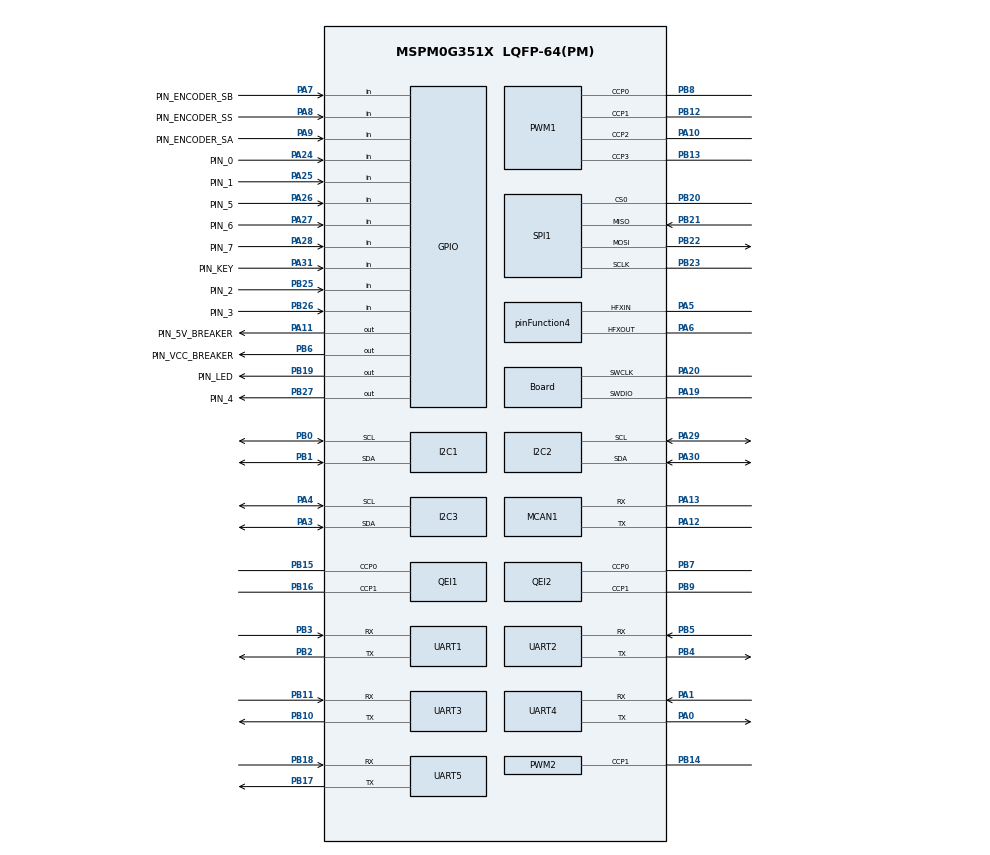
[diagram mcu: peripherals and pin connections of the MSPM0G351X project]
/**
 * @cliArgs --device "MSPM0G351X" --part "Default" --package "LQFP-64(PM)" --product "mspm0_sdk@2.10.00.04"
 * @versions {"tool":"1.27.0+4565"}
 */

/**
 * Import the modules used in this configuration.
 */
const Board  = scripting.addModule("/ti/driverlib/Board");
const GPIO   = scripting.addModule("/ti/driverlib/GPIO", {}, false);
const GPIO1  = GPIO.addInstance();
const GPIO2  = GPIO.addInstance();
const GPIO3  = GPIO.addInstance();
const GPIO4  = GPIO.addInstance();
const I2C    = scripting.addModule("/ti/driverlib/I2C", {}, false);
const I2C1   = I2C.addInstance();
const I2C2   = I2C.addInstance();
const I2C3   = I2C.addInstance();
const MCAN   = scripting.addModule("/ti/driverlib/MCAN", {}, false);
const MCAN1  = MCAN.addInstance();
const PWM    = scripting.addModule("/ti/driverlib/PWM", {}, false);
const PWM1   = PWM.addInstance();
const PWM2   = PWM.addInstance();
const QEI    = scripting.addModule("/ti/driverlib/QEI", {}, false);
const QEI1   = QEI.addInstance();
const QEI2   = QEI.addInstance();
const SPI    = scripting.addModule("/ti/driverlib/SPI", {}, false);
const SPI1   = SPI.addInstance();
const SYSCTL = scripting.addModule("/ti/driverlib/SYSCTL");
const UART   = scripting.addModule("/ti/driverlib/UART", {}, false);
const UART1  = UART.addInstance();
const UART2  = UART.addInstance();
const UART3  = UART.addInstance();
const UART4  = UART.addInstance();
const UART5  = UART.addInstance();

/**
 * Write custom configuration values to the imported modules.
 */
const divider2       = system.clockTree["HFCLK4MFPCLKDIV"];
divider2.divideValue = 10;

const divider9       = system.clockTree["UDIV"];
divider9.divideValue = 2;

const gate8  = system.clockTree["MFPCLKGATE"];
gate8.enable = true;

const mux4       = system.clockTree["EXHFMUX"];
mux4.inputSelect = "EXHFMUX_XTAL";

const mux8       = system.clockTree["HSCLKMUX"];
mux8.inputSelect = "HSCLKMUX_SYSPLL2X";

const mux10       = system.clockTree["MFPCLKMUX"];
mux10.inputSelect = "MFPCLKMUX_HFCLK";

const mux12       = system.clockTree["SYSPLLMUX"];
mux12.inputSelect = "zSYSPLLMUX_HFCLK";

const pinFunction4                        = system.clockTree["HFXT"];
pinFunction4.inputFreq                    = 40;
pinFunction4.enable                       = true;
pinFunction4.HFXTStartup                  = 255;
pinFunction4.HFCLKMonitor                 = true;
pinFunction4.peripheral.$assign           = "SYSCTL";
pinFunction4.peripheral.hfxInPin.$assign  = "PA5";
pinFunction4.peripheral.hfxOutPin.$assign = "PA6";

Board.configureUnused             = true;
Board.unusedDirection             = "INPUT";
Board.unusedInternalResistor      = "PULL_DOWN";
Board.peripheral.$assign          = "DEBUGSS";
Board.peripheral.swclkPin.$assign = "PA20";
Board.peripheral.swdioPin.$assign = "PA19";

GPIO1.$name                                 = "BREAKER";
GPIO1.associatedPins.create(2);
GPIO1.associatedPins[0].$name               = "PIN_VCC_BREAKER";
GPIO1.associatedPins[0].assignedPort        = "PORTB";
GPIO1.associatedPins[0].assignedPortSegment = "Lower";
GPIO1.associatedPins[0].assignedPin         = "6";
GPIO1.associatedPins[0].pin.$assign         = "PB6";
GPIO1.associatedPins[1].$name               = "PIN_5V_BREAKER";
GPIO1.associatedPins[1].assignedPort        = "PORTA";
GPIO1.associatedPins[1].assignedPin         = "11";
GPIO1.associatedPins[1].pin.$assign         = "PA11";

GPIO2.$name                          = "IO";
GPIO2.associatedPins.create(8);
GPIO2.associatedPins[0].$name        = "PIN_0";
GPIO2.associatedPins[0].direction    = "INPUT";
GPIO2.associatedPins[0].assignedPort = "PORTA";
GPIO2.associatedPins[0].assignedPin  = "24";
GPIO2.associatedPins[0].pin.$assign  = "PA24";
GPIO2.associatedPins[1].$name        = "PIN_1";
GPIO2.associatedPins[1].direction    = "INPUT";
GPIO2.associatedPins[1].assignedPort = "PORTA";
GPIO2.associatedPins[1].assignedPin  = "25";
GPIO2.associatedPins[1].pin.$assign  = "PA25";
GPIO2.associatedPins[2].$name        = "PIN_2";
GPIO2.associatedPins[2].direction    = "INPUT";
GPIO2.associatedPins[2].assignedPort = "PORTB";
GPIO2.associatedPins[2].assignedPin  = "25";
GPIO2.associatedPins[2].pin.$assign  = "PB25";
GPIO2.associatedPins[3].$name        = "PIN_3";
GPIO2.associatedPins[3].direction    = "INPUT";
GPIO2.associatedPins[3].assignedPort = "PORTB";
GPIO2.associatedPins[3].assignedPin  = "26";
GPIO2.associatedPins[3].pin.$assign  = "PB26";
GPIO2.associatedPins[4].$name        = "PIN_4";
GPIO2.associatedPins[4].assignedPort = "PORTB";
GPIO2.associatedPins[4].assignedPin  = "27";
GPIO2.associatedPins[4].pin.$assign  = "PB27";
GPIO2.associatedPins[5].$name        = "PIN_5";
GPIO2.associatedPins[5].direction    = "INPUT";
GPIO2.associatedPins[5].assignedPort = "PORTA";
GPIO2.associatedPins[5].assignedPin  = "26";
GPIO2.associatedPins[5].pin.$assign  = "PA26";
GPIO2.associatedPins[6].$name        = "PIN_6";
GPIO2.associatedPins[6].direction    = "INPUT";
GPIO2.associatedPins[6].assignedPort = "PORTA";
GPIO2.associatedPins[6].assignedPin  = "27";
GPIO2.associatedPins[6].pin.$assign  = "PA27";
GPIO2.associatedPins[7].$name        = "PIN_7";
GPIO2.associatedPins[7].assignedPort = "PORTA";
GPIO2.associatedPins[7].assignedPin  = "28";
GPIO2.associatedPins[7].direction    = "INPUT";
GPIO2.associatedPins[7].pin.$assign  = "PA28";

GPIO3.$name                          = "KEY";
GPIO3.associatedPins.create(4);
GPIO3.associatedPins[0].$name        = "PIN_KEY";
GPIO3.associatedPins[0].direction    = "INPUT";
GPIO3.associatedPins[0].assignedPort = "PORTA";
GPIO3.associatedPins[0].assignedPin  = "31";
GPIO3.associatedPins[0].polarity     = "RISE";
GPIO3.associatedPins[0].interruptEn  = true;
GPIO3.associatedPins[0].pin.$assign  = "PA31";
GPIO3.associatedPins[1].assignedPort = "PORTA";
GPIO3.associatedPins[1].assignedPin  = "9";
GPIO3.associatedPins[1].$name        = "PIN_ENCODER_SA";
GPIO3.associatedPins[1].direction    = "INPUT";
GPIO3.associatedPins[1].polarity     = "RISE_FALL";
GPIO3.associatedPins[1].interruptEn  = true;
GPIO3.associatedPins[1].pin.$assign  = "PA9";
GPIO3.associatedPins[2].$name        = "PIN_ENCODER_SS";
GPIO3.associatedPins[2].assignedPort = "PORTA";
GPIO3.associatedPins[2].assignedPin  = "8";
GPIO3.associatedPins[2].direction    = "INPUT";
GPIO3.associatedPins[2].polarity     = "RISE";
GPIO3.associatedPins[2].interruptEn  = true;
GPIO3.associatedPins[2].pin.$assign  = "PA8";
GPIO3.associatedPins[3].$name        = "PIN_ENCODER_SB";
GPIO3.associatedPins[3].assignedPort = "PORTA";
GPIO3.associatedPins[3].assignedPin  = "7";
GPIO3.associatedPins[3].direction    = "INPUT";
GPIO3.associatedPins[3].polarity     = "RISE_FALL";
GPIO3.associatedPins[3].interruptEn  = true;
GPIO3.associatedPins[3].pin.$assign  = "PA7";

GPIO4.$name                          = "LED";
GPIO4.associatedPins[0].$name        = "PIN_LED";
GPIO4.associatedPins[0].assignedPort = "PORTB";
GPIO4.associatedPins[0].assignedPin  = "19";
GPIO4.associatedPins[0].pin.$assign  = "PB19";

I2C1.$name                             = "I2C_0_OLED";
I2C1.basicEnableController             = true;
I2C1.basicControllerBusSpeed           = 400000;
I2C1.peripheral.$assign                = "I2C0";
I2C1.peripheral.sdaPin.$assign         = "PB1";
I2C1.peripheral.sclPin.$assign         = "PB0";
I2C1.sdaPinConfig.hideOutputInversion  = scripting.forceWrite(false);
I2C1.sdaPinConfig.onlyInternalResistor = scripting.forceWrite(false);
I2C1.sdaPinConfig.passedPeripheralType = scripting.forceWrite("Digital");
I2C1.sdaPinConfig.$name                = "ti_driverlib_gpio_GPIOPinGeneric14";
I2C1.sclPinConfig.hideOutputInversion  = scripting.forceWrite(false);
I2C1.sclPinConfig.onlyInternalResistor = scripting.forceWrite(false);
I2C1.sclPinConfig.passedPeripheralType = scripting.forceWrite("Digital");
I2C1.sclPinConfig.$name                = "ti_driverlib_gpio_GPIOPinGeneric15";

I2C2.$name                             = "I2C_2";
I2C2.basicEnableController             = true;
I2C2.basicControllerBusSpeed           = 400000;
I2C2.peripheral.$assign                = "I2C2";
I2C2.peripheral.sdaPin.$assign         = "PA30";
I2C2.peripheral.sclPin.$assign         = "PA29";
I2C2.sdaPinConfig.hideOutputInversion  = scripting.forceWrite(false);
I2C2.sdaPinConfig.onlyInternalResistor = scripting.forceWrite(false);
I2C2.sdaPinConfig.passedPeripheralType = scripting.forceWrite("Digital");
I2C2.sdaPinConfig.$name                = "ti_driverlib_gpio_GPIOPinGeneric16";
I2C2.sclPinConfig.hideOutputInversion  = scripting.forceWrite(false);
I2C2.sclPinConfig.onlyInternalResistor = scripting.forceWrite(false);
I2C2.sclPinConfig.passedPeripheralType = scripting.forceWrite("Digital");
I2C2.sclPinConfig.$name                = "ti_driverlib_gpio_GPIOPinGeneric17";

I2C3.$name                             = "I2C_1";
I2C3.basicEnableController             = true;
I2C3.basicControllerBusSpeed           = 400000;
I2C3.peripheral.$assign                = "I2C1";
I2C3.peripheral.sdaPin.$assign         = "PA3";
I2C3.peripheral.sclPin.$assign         = "PA4";
I2C3.sdaPinConfig.hideOutputInversion  = scripting.forceWrite(false);
I2C3.sdaPinConfig.onlyInternalResistor = scripting.forceWrite(false);
I2C3.sdaPinConfig.passedPeripheralType = scripting.forceWrite("Digital");
I2C3.sdaPinConfig.$name                = "ti_driverlib_gpio_GPIOPinGeneric18";
I2C3.sclPinConfig.hideOutputInversion  = scripting.forceWrite(false);
I2C3.sclPinConfig.onlyInternalResistor = scripting.forceWrite(false);
I2C3.sclPinConfig.passedPeripheralType = scripting.forceWrite("Digital");
I2C3.sclPinConfig.$name                = "ti_driverlib_gpio_GPIOPinGeneric19";

MCAN1.$name                    = "MCAN0";
MCAN1.fdMode                   = false;
MCAN1.desiredNomRate           = 1000;
MCAN1.stdFiltElem              = "001";
MCAN1.stdFiltType              = "00";
MCAN1.stdFiltID2               = 2047;
MCAN1.extFiltElem              = "001";
MCAN1.txBufElemSize            = "DL_MCAN_ELEM_SIZE_8BYTES";
MCAN1.rxBufElemSize            = "DL_MCAN_ELEM_SIZE_8BYTES";
MCAN1.rxFIFO0ElemSize          = "DL_MCAN_ELEM_SIZE_8BYTES";
MCAN1.rxFIFO1ElemSize          = "DL_MCAN_ELEM_SIZE_8BYTES";
MCAN1.enableInterrupt          = true;
MCAN1.interruptLine            = ["DL_MCAN_INTR_LINE_NUM_0"];
MCAN1.interruptLine0Flag       = ["DL_MCAN_INTERRUPT_RF0N","DL_MCAN_INTERRUPT_TEFN"];
MCAN1.interruptFlags           = ["DL_MCAN_INTERRUPT_RF0N","DL_MCAN_INTERRUPT_TEFN"];
MCAN1.m0interrupts             = ["DL_MCAN_MSP_INTERRUPT_LINE0"];
MCAN1.spPercent                = 75;
MCAN1.peripheral.$assign       = "CANFD0";
MCAN1.peripheral.rxPin.$assign = "PA13";
MCAN1.peripheral.txPin.$assign = "PA12";
MCAN1.txPinConfig.$name        = "ti_driverlib_gpio_GPIOPinGeneric8";
MCAN1.rxPinConfig.$name        = "ti_driverlib_gpio_GPIOPinGeneric9";

PWM1.$name                              = "PWM_A0";
PWM1.ccIndex                            = [0,1,2,3];
PWM1.timerStartTimer                    = true;
PWM1.PWM_CHANNEL_0.$name                = "ti_driverlib_pwm_PWMTimerCC0";
PWM1.PWM_CHANNEL_1.$name                = "ti_driverlib_pwm_PWMTimerCC1";
PWM1.ccp0PinConfig.direction            = scripting.forceWrite("OUTPUT");
PWM1.ccp0PinConfig.hideOutputInversion  = scripting.forceWrite(false);
PWM1.ccp0PinConfig.onlyInternalResistor = scripting.forceWrite(false);
PWM1.ccp0PinConfig.passedPeripheralType = scripting.forceWrite("Digital");
PWM1.ccp0PinConfig.$name                = "ti_driverlib_gpio_GPIOPinGeneric4";
PWM1.ccp1PinConfig.direction            = scripting.forceWrite("OUTPUT");
PWM1.ccp1PinConfig.hideOutputInversion  = scripting.forceWrite(false);
PWM1.ccp1PinConfig.onlyInternalResistor = scripting.forceWrite(false);
PWM1.ccp1PinConfig.passedPeripheralType = scripting.forceWrite("Digital");
PWM1.ccp1PinConfig.$name                = "ti_driverlib_gpio_GPIOPinGeneric5";
PWM1.peripheral.$assign                 = "TIMA0";
PWM1.peripheral.ccp0Pin.$assign         = "PB8";
PWM1.peripheral.ccp1Pin.$assign         = "PB12";
PWM1.peripheral.ccp2Pin.$assign         = "PA10";
PWM1.peripheral.ccp3Pin.$assign         = "PB13";
PWM1.PWM_CHANNEL_2.$name                = "ti_driverlib_pwm_PWMTimerCC2";
PWM1.PWM_CHANNEL_3.$name                = "ti_driverlib_pwm_PWMTimerCC3";
PWM1.ccp2PinConfig.$name                = "ti_driverlib_gpio_GPIOPinGeneric6";
PWM1.ccp3PinConfig.$name                = "ti_driverlib_gpio_GPIOPinGeneric7";

PWM2.ccIndex                            = [1];
PWM2.$name                              = "PWM_G12_BUZZER";
PWM2.timerStartTimer                    = true;
PWM2.ccp1PinConfig.direction            = scripting.forceWrite("OUTPUT");
PWM2.ccp1PinConfig.hideOutputInversion  = scripting.forceWrite(false);
PWM2.ccp1PinConfig.onlyInternalResistor = scripting.forceWrite(false);
PWM2.ccp1PinConfig.passedPeripheralType = scripting.forceWrite("Digital");
PWM2.ccp1PinConfig.$name                = "ti_driverlib_gpio_GPIOPinGeneric31";
PWM2.peripheral.$assign                 = "TIMG12";
PWM2.peripheral.ccp1Pin.$assign         = "PB14";
PWM2.PWM_CHANNEL_1.$name                = "ti_driverlib_pwm_PWMTimerCC4";

QEI1.$name                              = "QEI_G8";
QEI1.timerStartTimer                    = true;
QEI1.peripheral.$assign                 = "TIMG8";
QEI1.peripheral.ccp0Pin.$assign         = "PB15";
QEI1.peripheral.ccp1Pin.$assign         = "PB16";
QEI1.ccp0PinConfig.hideOutputInversion  = scripting.forceWrite(false);
QEI1.ccp0PinConfig.onlyInternalResistor = scripting.forceWrite(false);
QEI1.ccp0PinConfig.passedPeripheralType = scripting.forceWrite("Digital");
QEI1.ccp0PinConfig.$name                = "ti_driverlib_gpio_GPIOPinGeneric0";
QEI1.ccp1PinConfig.hideOutputInversion  = scripting.forceWrite(false);
QEI1.ccp1PinConfig.onlyInternalResistor = scripting.forceWrite(false);
QEI1.ccp1PinConfig.passedPeripheralType = scripting.forceWrite("Digital");
QEI1.ccp1PinConfig.$name                = "ti_driverlib_gpio_GPIOPinGeneric1";

QEI2.$name                              = "QEI_G9";
QEI2.timerStartTimer                    = true;
QEI2.peripheral.$assign                 = "TIMG9";
QEI2.peripheral.ccp0Pin.$assign         = "PB7";
QEI2.peripheral.ccp1Pin.$assign         = "PB9";
QEI2.ccp0PinConfig.hideOutputInversion  = scripting.forceWrite(false);
QEI2.ccp0PinConfig.onlyInternalResistor = scripting.forceWrite(false);
QEI2.ccp0PinConfig.passedPeripheralType = scripting.forceWrite("Digital");
QEI2.ccp0PinConfig.$name                = "ti_driverlib_gpio_GPIOPinGeneric2";
QEI2.ccp1PinConfig.hideOutputInversion  = scripting.forceWrite(false);
QEI2.ccp1PinConfig.onlyInternalResistor = scripting.forceWrite(false);
QEI2.ccp1PinConfig.passedPeripheralType = scripting.forceWrite("Digital");
QEI2.ccp1PinConfig.$name                = "ti_driverlib_gpio_GPIOPinGeneric3";

SPI1.$name                              = "SPI_1";
SPI1.peripheral.$assign                 = "SPI1";
SPI1.peripheral.sclkPin.$assign         = "PB23";
SPI1.peripheral.mosiPin.$assign         = "PB22";
SPI1.peripheral.misoPin.$assign         = "PB21";
SPI1.peripheral.cs0Pin.$assign          = "PB20";
SPI1.sclkPinConfig.direction            = scripting.forceWrite("OUTPUT");
SPI1.sclkPinConfig.onlyInternalResistor = scripting.forceWrite(false);
SPI1.sclkPinConfig.passedPeripheralType = scripting.forceWrite("Digital");
SPI1.sclkPinConfig.$name                = "ti_driverlib_gpio_GPIOPinGeneric10";
SPI1.mosiPinConfig.direction            = scripting.forceWrite("OUTPUT");
SPI1.mosiPinConfig.hideOutputInversion  = scripting.forceWrite(false);
SPI1.mosiPinConfig.onlyInternalResistor = scripting.forceWrite(false);
SPI1.mosiPinConfig.passedPeripheralType = scripting.forceWrite("Digital");
SPI1.mosiPinConfig.$name                = "ti_driverlib_gpio_GPIOPinGeneric11";
SPI1.misoPinConfig.onlyInternalResistor = scripting.forceWrite(false);
SPI1.misoPinConfig.passedPeripheralType = scripting.forceWrite("Digital");
SPI1.misoPinConfig.$name                = "ti_driverlib_gpio_GPIOPinGeneric12";
SPI1.cs0PinConfig.direction             = scripting.forceWrite("OUTPUT");
SPI1.cs0PinConfig.hideOutputInversion   = scripting.forceWrite(false);
SPI1.cs0PinConfig.onlyInternalResistor  = scripting.forceWrite(false);
SPI1.cs0PinConfig.passedPeripheralType  = scripting.forceWrite("Digital");
SPI1.cs0PinConfig.$name                 = "ti_driverlib_gpio_GPIOPinGeneric13";

SYSCTL.clockTreeEn = true;

UART1.$name                             = "UART_3";
UART1.targetBaudRate                    = 115200;
UART1.enableFIFO                        = true;
UART1.rxFifoThreshold                   = "DL_UART_RX_FIFO_LEVEL_FULL";
UART1.txFifoThreshold                   = "DL_UART_TX_FIFO_LEVEL_EMPTY";
UART1.enabledInterrupts                 = ["DMA_DONE_TX","RX","RX_TIMEOUT_ERROR"];
UART1.enabledDMATXTriggers              = "DL_UART_DMA_INTERRUPT_TX";
UART1.peripheral.$assign                = "UART3";
UART1.peripheral.rxPin.$assign          = "PB3";
UART1.peripheral.txPin.$assign          = "PB2";
UART1.txPinConfig.$name                 = "ti_driverlib_gpio_GPIOPinGeneric20";
UART1.txPinConfig.direction             = scripting.forceWrite("OUTPUT");
UART1.txPinConfig.hideOutputInversion   = scripting.forceWrite(false);
UART1.txPinConfig.onlyInternalResistor  = scripting.forceWrite(false);
UART1.txPinConfig.passedPeripheralType  = scripting.forceWrite("Digital");
UART1.rxPinConfig.$name                 = "ti_driverlib_gpio_GPIOPinGeneric21";
UART1.rxPinConfig.hideOutputInversion   = scripting.forceWrite(false);
UART1.rxPinConfig.onlyInternalResistor  = scripting.forceWrite(false);
UART1.rxPinConfig.passedPeripheralType  = scripting.forceWrite("Digital");
UART1.DMA_CHANNEL_TX.$name              = "DMA_CH2";
UART1.DMA_CHANNEL_TX.addressMode        = "b2f";
UART1.DMA_CHANNEL_TX.srcLength          = "BYTE";
UART1.DMA_CHANNEL_TX.dstLength          = "BYTE";
UART1.DMA_CHANNEL_TX.peripheral.$assign = "DMA_CH2";

UART2.$name                             = "UART_1";
UART2.targetBaudRate                    = 115200;
UART2.enableFIFO                        = true;
UART2.rxFifoThreshold                   = "DL_UART_RX_FIFO_LEVEL_FULL";
UART2.txFifoThreshold                   = "DL_UART_TX_FIFO_LEVEL_EMPTY";
UART2.enabledInterrupts                 = ["DMA_DONE_TX","RX","RX_TIMEOUT_ERROR"];
UART2.enabledDMATXTriggers              = "DL_UART_DMA_INTERRUPT_TX";
UART2.peripheral.$assign                = "UART1";
UART2.peripheral.rxPin.$assign          = "PB5";
UART2.peripheral.txPin.$assign          = "PB4";
UART2.txPinConfig.$name                 = "ti_driverlib_gpio_GPIOPinGeneric22";
UART2.rxPinConfig.$name                 = "ti_driverlib_gpio_GPIOPinGeneric23";
UART2.DMA_CHANNEL_TX.$name              = "DMA_CH1";
UART2.DMA_CHANNEL_TX.addressMode        = "b2f";
UART2.DMA_CHANNEL_TX.srcLength          = "BYTE";
UART2.DMA_CHANNEL_TX.dstLength          = "BYTE";
UART2.DMA_CHANNEL_TX.peripheral.$assign = "DMA_CH1";

UART3.$name                             = "UART_4";
UART3.targetBaudRate                    = 115200;
UART3.enableFIFO                        = true;
UART3.rxFifoThreshold                   = "DL_UART_RX_FIFO_LEVEL_FULL";
UART3.txFifoThreshold                   = "DL_UART_TX_FIFO_LEVEL_EMPTY";
UART3.enabledInterrupts                 = ["DMA_DONE_TX","RX","RX_TIMEOUT_ERROR"];
UART3.enabledDMATXTriggers              = "DL_UART_DMA_INTERRUPT_TX";
UART3.peripheral.$assign                = "UART4";
UART3.peripheral.rxPin.$assign          = "PB11";
UART3.peripheral.txPin.$assign          = "PB10";
UART3.txPinConfig.$name                 = "ti_driverlib_gpio_GPIOPinGeneric24";
UART3.txPinConfig.direction             = scripting.forceWrite("OUTPUT");
UART3.txPinConfig.hideOutputInversion   = scripting.forceWrite(false);
UART3.txPinConfig.onlyInternalResistor  = scripting.forceWrite(false);
UART3.txPinConfig.passedPeripheralType  = scripting.forceWrite("Digital");
UART3.rxPinConfig.$name                 = "ti_driverlib_gpio_GPIOPinGeneric25";
UART3.rxPinConfig.hideOutputInversion   = scripting.forceWrite(false);
UART3.rxPinConfig.onlyInternalResistor  = scripting.forceWrite(false);
UART3.rxPinConfig.passedPeripheralType  = scripting.forceWrite("Digital");
UART3.DMA_CHANNEL_TX.$name              = "DMA_CH3";
UART3.DMA_CHANNEL_TX.addressMode        = "b2f";
UART3.DMA_CHANNEL_TX.srcLength          = "BYTE";
UART3.DMA_CHANNEL_TX.dstLength          = "BYTE";
UART3.DMA_CHANNEL_TX.peripheral.$assign = "DMA_CH3";

UART4.$name                             = "UART_0";
UART4.targetBaudRate                    = 115200;
UART4.enableFIFO                        = true;
UART4.rxFifoThreshold                   = "DL_UART_RX_FIFO_LEVEL_FULL";
UART4.txFifoThreshold                   = "DL_UART_TX_FIFO_LEVEL_EMPTY";
UART4.enabledInterrupts                 = ["DMA_DONE_TX","RX","RX_TIMEOUT_ERROR"];
UART4.enabledDMATXTriggers              = "DL_UART_DMA_INTERRUPT_TX";
UART4.peripheral.$assign                = "UART0";
UART4.peripheral.rxPin.$assign          = "PA1";
UART4.peripheral.txPin.$assign          = "PA0";
UART4.txPinConfig.$name                 = "ti_driverlib_gpio_GPIOPinGeneric26";
UART4.txPinConfig.direction             = scripting.forceWrite("OUTPUT");
UART4.txPinConfig.hideOutputInversion   = scripting.forceWrite(false);
UART4.txPinConfig.onlyInternalResistor  = scripting.forceWrite(false);
UART4.txPinConfig.passedPeripheralType  = scripting.forceWrite("Digital");
UART4.rxPinConfig.$name                 = "ti_driverlib_gpio_GPIOPinGeneric27";
UART4.rxPinConfig.hideOutputInversion   = scripting.forceWrite(false);
UART4.rxPinConfig.onlyInternalResistor  = scripting.forceWrite(false);
UART4.rxPinConfig.passedPeripheralType  = scripting.forceWrite("Digital");
UART4.DMA_CHANNEL_TX.$name              = "DMA_CH0";
UART4.DMA_CHANNEL_TX.addressMode        = "b2f";
UART4.DMA_CHANNEL_TX.srcLength          = "BYTE";
UART4.DMA_CHANNEL_TX.dstLength          = "BYTE";
UART4.DMA_CHANNEL_TX.peripheral.$assign = "DMA_CH0";

UART5.$name                             = "UART_7";
UART5.targetBaudRate                    = 115200;
UART5.enableFIFO                        = true;
UART5.rxFifoThreshold                   = "DL_UART_RX_FIFO_LEVEL_FULL";
UART5.txFifoThreshold                   = "DL_UART_TX_FIFO_LEVEL_EMPTY";
UART5.enabledInterrupts                 = ["DMA_DONE_TX","RX","RX_TIMEOUT_ERROR"];
UART5.enabledDMATXTriggers              = "DL_UART_DMA_INTERRUPT_TX";
UART5.peripheral.$assign                = "UART7";
UART5.peripheral.rxPin.$assign          = "PB18";
UART5.peripheral.txPin.$assign          = "PB17";
UART5.txPinConfig.$name                 = "ti_driverlib_gpio_GPIOPinGeneric28";
UART5.txPinConfig.direction             = scripting.forceWrite("OUTPUT");
UART5.txPinConfig.hideOutputInversion   = scripting.forceWrite(false);
UART5.txPinConfig.onlyInternalResistor  = scripting.forceWrite(false);
UART5.txPinConfig.passedPeripheralType  = scripting.forceWrite("Digital");
UART5.rxPinConfig.$name                 = "ti_driverlib_gpio_GPIOPinGeneric29";
UART5.rxPinConfig.hideOutputInversion   = scripting.forceWrite(false);
UART5.rxPinConfig.onlyInternalResistor  = scripting.forceWrite(false);
UART5.rxPinConfig.passedPeripheralType  = scripting.forceWrite("Digital");
UART5.DMA_CHANNEL_TX.$name              = "DMA_CH4";
UART5.DMA_CHANNEL_TX.addressMode        = "b2f";
UART5.DMA_CHANNEL_TX.srcLength          = "BYTE";
UART5.DMA_CHANNEL_TX.dstLength          = "BYTE";
UART5.DMA_CHANNEL_TX.peripheral.$assign = "DMA_CH4";
